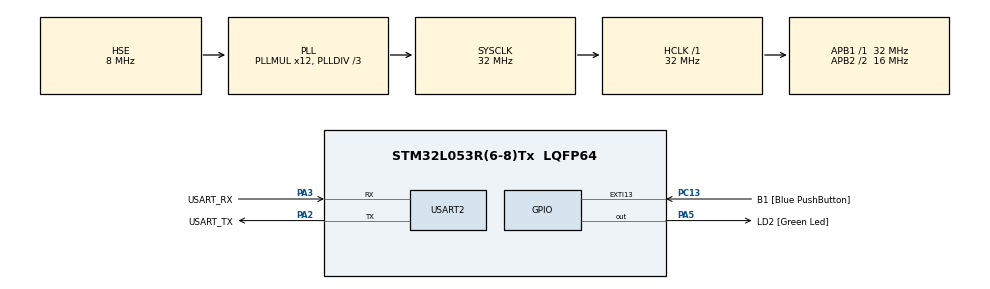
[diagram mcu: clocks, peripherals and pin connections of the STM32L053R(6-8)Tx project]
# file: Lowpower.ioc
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FREERTOS.Tasks01=defaultTask,0,128,StartDefaultTask,Default
Mcu.Family=STM32L0
Mcu.Name=STM32L053R(6-8)Tx
Mcu.Package=LQFP64
NVIC.EXTI4_15_IRQn=true\:3\:0\:false\:false\:true
NVIC.TIM6_DAC_IRQn=true\:0\:0\:false\:false\:true
NVIC.TimeBase=TIM6_DAC_IRQn
NVIC.TimeBaseIP=TIM6
PA13.GPIO_Label=TMS
PA13.Mode=Serial_Wire
PA13.Signal=SYS_SWDIO
PA14.GPIO_Label=TCK
PA14.Mode=Serial_Wire
PA14.Signal=SYS_SWCLK
PA2.GPIO_Label=USART_TX
PA2.Mode=Asynchronous
PA2.Signal=USART2_TX
PA3.GPIO_Label=USART_RX
PA3.Mode=Asynchronous
PA3.Signal=USART2_RX
PA5.GPIO_Label=LD2 [Green Led]
PA5.Signal=GPIO_Output
PC13.GPIO_Label=B1 [Blue PushButton]
PC13.GPIO_ModeDefaultEXTI=GPIO_MODE_IT_RISING
PC13.GPIO_PuPd=GPIO_PULLUP
PC13.Signal=GPXTI13
PC14-OSC32_IN.Mode=LSE-External-Oscillator
PC14-OSC32_IN.Signal=RCC_OSC32_IN
PC15-OSC32_OUT.Mode=LSE-External-Oscillator
PC15-OSC32_OUT.Signal=RCC_OSC32_OUT
PH0-OSC_IN.Signal=RCC_OSC_IN
ProjectManager.HeapSize=0x400
ProjectManager.StackSize=0x800
ProjectManager.TargetToolchain=TrueSTUDIO
RCC.AHBFreq_Value=32000000
RCC.APB1Freq_Value=32000000
RCC.APB1TimFreq_Value=32000000
RCC.APB2CLKDivider=RCC_HCLK_DIV2
RCC.APB2Freq_Value=16000000
RCC.APB2TimFreq_Value=32000000
RCC.HCLKFreq_Value=32000000
RCC.HSE_VALUE=8000000
RCC.HSI16_VALUE=16000000
RCC.HSI48_VALUE=48000000
RCC.HSI_VALUE=16000000
RCC.MSI_VALUE=2097000
RCC.PLLDIV=RCC_PLLDIV_3
RCC.PLLMUL=RCC_PLLMUL_6
RCC.RTCClockSelection=RCC_RTCCLKSOURCE_LSE
RCC.RTCClockSelectionVirtual=RCC_RTCCLKSOURCE_LSE
RCC.SYSCLKFreq_VALUE=32000000
RCC.SYSCLKSource=RCC_SYSCLKSOURCE_PLLCLK
RCC.VCOOutputFreq_Value=96000000
USART2.WordLength=UART_WORDLENGTH_8B
VP_FREERTOS_VS_ENABLE.Mode=Enabled
VP_RTC_VS_RTC_Alarm_A_Intern.Mode=Alarm A
VP_RTC_VS_RTC_WakeUp_intern.Mode=WakeUp
VP_SYS_VS_tim6.Mode=TIM6
board=NUCLEO-L053R8

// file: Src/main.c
/**
  ******************************************************************************
  * File Name          : main.c
  * Description        : Main program body
  ******************************************************************************
  *
  * COPYRIGHT(c) 2016 STMicroelectronics
  *
  * Redistribution and use in source and binary forms, with or without modification,
  * are permitted provided that the following conditions are met:
  *   1. Redistributions of source code must retain the above copyright notice,
  *      this list of conditions and the following disclaimer.
  *   2. Redistributions in binary form must reproduce the above copyright notice,
  *      this list of conditions and the following disclaimer in the documentation
  *      and/or other materials provided with the distribution.
  *   3. Neither the name of STMicroelectronics nor the names of its contributors
  *      may be used to endorse or promote products derived from this software
  *      without specific prior written permission.
  *
  * THIS SOFTWARE IS PROVIDED BY THE COPYRIGHT HOLDERS AND CONTRIBUTORS "AS IS"
  * AND ANY EXPRESS OR IMPLIED WARRANTIES, INCLUDING, BUT NOT LIMITED TO, THE
  * IMPLIED WARRANTIES OF MERCHANTABILITY AND FITNESS FOR A PARTICULAR PURPOSE ARE
  * DISCLAIMED. IN NO EVENT SHALL THE COPYRIGHT HOLDER OR CONTRIBUTORS BE LIABLE
  * FOR ANY DIRECT, INDIRECT, INCIDENTAL, SPECIAL, EXEMPLARY, OR CONSEQUENTIAL
  * DAMAGES (INCLUDING, BUT NOT LIMITED TO, PROCUREMENT OF SUBSTITUTE GOODS OR
  * SERVICES; LOSS OF USE, DATA, OR PROFITS; OR BUSINESS INTERRUPTION) HOWEVER
  * CAUSED AND ON ANY THEORY OF LIABILITY, WHETHER IN CONTRACT, STRICT LIABILITY,
  * OR TORT (INCLUDING NEGLIGENCE OR OTHERWISE) ARISING IN ANY WAY OUT OF THE USE
  * OF THIS SOFTWARE, EVEN IF ADVISED OF THE POSSIBILITY OF SUCH DAMAGE.
  *
  ******************************************************************************
  */
#include "stm32l0xx_hal.h"
#include "cmsis_os.h"

/* USER CODE BEGIN Includes */

#include <stdio.h>

/* USER CODE END Includes */

RTC_HandleTypeDef hrtc;

UART_HandleTypeDef huart2;

osThreadId defaultTaskHandle;

/* USER CODE BEGIN PV */
/* Private variables ---------------------------------------------------------*/

/* USER CODE END PV */

void SystemClock_Config(void);
static void MX_GPIO_Init(void);
static void MX_RTC_Init(void);
static void MX_USART2_UART_Init(void);
void StartDefaultTask(void const * argument);

/* USER CODE BEGIN PFP */
/* Private function prototypes -----------------------------------------------*/

/* USER CODE END PFP */

int main(void)
{

  /* MCU Configuration----------------------------------------------------------*/

  /* Reset of all peripherals, Initializes the Flash interface and the Systick. */
  HAL_Init();

  /* Configure the system clock */
  SystemClock_Config();

  /* Initialize all configured peripherals */
  MX_GPIO_Init();
  MX_RTC_Init();
  MX_USART2_UART_Init();

  /* USER CODE BEGIN 2 */
  HAL_UART_Transmit(&huart2, (uint8_t *)"\n\rDuvitech \302\2512016\n\r", 19, 0x0f);
  /* USER CODE END 2 */

  /* Create the thread(s) */
  /* definition and creation of defaultTask */
  osThreadDef(defaultTask, StartDefaultTask, osPriorityNormal, 0, 128);
  defaultTaskHandle = osThreadCreate(osThread(defaultTask), NULL);

  /* Start scheduler */
  osKernelStart();

  /* We should never get here as control is now taken by the scheduler */

  /* Infinite loop */
  while (1)
  {

  }

}

/** System Clock Configuration
*/
/** System Clock Configuration
*/
void SystemClock_Config(void)
{

  RCC_OscInitTypeDef RCC_OscInitStruct;
  RCC_ClkInitTypeDef RCC_ClkInitStruct;
  RCC_PeriphCLKInitTypeDef PeriphClkInit;

  __HAL_RCC_PWR_CLK_ENABLE();

  __HAL_PWR_VOLTAGESCALING_CONFIG(PWR_REGULATOR_VOLTAGE_SCALE1);

  RCC_OscInitStruct.OscillatorType = RCC_OSCILLATORTYPE_HSE|RCC_OSCILLATORTYPE_LSE;
  RCC_OscInitStruct.HSEState = RCC_HSE_BYPASS;
  RCC_OscInitStruct.LSEState = RCC_LSE_ON;
  RCC_OscInitStruct.PLL.PLLState = RCC_PLL_ON;
  RCC_OscInitStruct.PLL.PLLSource = RCC_PLLSOURCE_HSE;
  RCC_OscInitStruct.PLL.PLLMUL = RCC_PLLMUL_12;
  RCC_OscInitStruct.PLL.PLLDIV = RCC_PLLDIV_3;
  HAL_RCC_OscConfig(&RCC_OscInitStruct);

  RCC_ClkInitStruct.ClockType = RCC_CLOCKTYPE_HCLK|RCC_CLOCKTYPE_SYSCLK
                              |RCC_CLOCKTYPE_PCLK1|RCC_CLOCKTYPE_PCLK2;
  RCC_ClkInitStruct.SYSCLKSource = RCC_SYSCLKSOURCE_PLLCLK;
  RCC_ClkInitStruct.AHBCLKDivider = RCC_SYSCLK_DIV1;
  RCC_ClkInitStruct.APB1CLKDivider = RCC_HCLK_DIV1;
  RCC_ClkInitStruct.APB2CLKDivider = RCC_HCLK_DIV2;
  HAL_RCC_ClockConfig(&RCC_ClkInitStruct, FLASH_LATENCY_1);

  PeriphClkInit.PeriphClockSelection = RCC_PERIPHCLK_USART2|RCC_PERIPHCLK_RTC;
  PeriphClkInit.Usart2ClockSelection = RCC_USART2CLKSOURCE_PCLK1;
  PeriphClkInit.RTCClockSelection = RCC_RTCCLKSOURCE_LSE;
  HAL_RCCEx_PeriphCLKConfig(&PeriphClkInit);

  HAL_SYSTICK_Config(HAL_RCC_GetHCLKFreq()/1000);

  HAL_SYSTICK_CLKSourceConfig(SYSTICK_CLKSOURCE_HCLK);

  /* SysTick_IRQn interrupt configuration */
  HAL_NVIC_SetPriority(SysTick_IRQn, 3, 0);
}

/* RTC init function */
void MX_RTC_Init(void)
{

  RTC_TimeTypeDef sTime;
  RTC_DateTypeDef sDate;
  RTC_AlarmTypeDef sAlarm;

    /**Initialize RTC and set the Time and Date
    */
  hrtc.Instance = RTC;
  hrtc.Init.HourFormat = RTC_HOURFORMAT_24;
  hrtc.Init.AsynchPrediv = 127;
  hrtc.Init.SynchPrediv = 255;
  hrtc.Init.OutPut = RTC_OUTPUT_DISABLE;
  hrtc.Init.OutPutRemap = RTC_OUTPUT_REMAP_NONE;
  hrtc.Init.OutPutPolarity = RTC_OUTPUT_POLARITY_HIGH;
  hrtc.Init.OutPutType = RTC_OUTPUT_TYPE_OPENDRAIN;
  HAL_RTC_Init(&hrtc);

  sTime.Hours = 0x0;
  sTime.Minutes = 0x0;
  sTime.Seconds = 0x0;
  sTime.DayLightSaving = RTC_DAYLIGHTSAVING_NONE;
  sTime.StoreOperation = RTC_STOREOPERATION_RESET;
  HAL_RTC_SetTime(&hrtc, &sTime, RTC_FORMAT_BCD);

  sDate.WeekDay = RTC_WEEKDAY_MONDAY;
  sDate.Month = RTC_MONTH_JANUARY;
  sDate.Date = 0x1;
  sDate.Year = 0x0;

  HAL_RTC_SetDate(&hrtc, &sDate, RTC_FORMAT_BCD);

    /**Enable the Alarm A
    */
  sAlarm.AlarmTime.Hours = 0x0;
  sAlarm.AlarmTime.Minutes = 0x0;
  sAlarm.AlarmTime.Seconds = 0x0;
  sAlarm.AlarmTime.SubSeconds = 0x0;
  sAlarm.AlarmTime.DayLightSaving = RTC_DAYLIGHTSAVING_NONE;
  sAlarm.AlarmTime.StoreOperation = RTC_STOREOPERATION_RESET;
  sAlarm.AlarmMask = RTC_ALARMMASK_NONE;
  sAlarm.AlarmSubSecondMask = RTC_ALARMSUBSECONDMASK_ALL;
  sAlarm.AlarmDateWeekDaySel = RTC_ALARMDATEWEEKDAYSEL_DATE;
  sAlarm.AlarmDateWeekDay = 0x1;
  sAlarm.Alarm = RTC_ALARM_A;
  HAL_RTC_SetAlarm(&hrtc, &sAlarm, RTC_FORMAT_BCD);

    /**Enable the WakeUp
    */
  HAL_RTCEx_SetWakeUpTimer(&hrtc, 0, RTC_WAKEUPCLOCK_RTCCLK_DIV16);

}

/* USART2 init function */
void MX_USART2_UART_Init(void)
{

  huart2.Instance = USART2;
  huart2.Init.BaudRate = 115200;
  huart2.Init.WordLength = UART_WORDLENGTH_8B;
  huart2.Init.StopBits = UART_STOPBITS_1;
  huart2.Init.Parity = UART_PARITY_NONE;
  huart2.Init.Mode = UART_MODE_TX_RX;
  huart2.Init.HwFlowCtl = UART_HWCONTROL_NONE;
  huart2.Init.OverSampling = UART_OVERSAMPLING_16;
  huart2.Init.OneBitSampling = UART_ONE_BIT_SAMPLE_DISABLE;
  huart2.AdvancedInit.AdvFeatureInit = UART_ADVFEATURE_NO_INIT;
  HAL_UART_Init(&huart2);

}

/** Configure pins as
        * Analog
        * Input
        * Output
        * EVENT_OUT
        * EXTI
        * Free pins are configured automatically as Analog (this feature is enabled through
        * the Code Generation settings)
*/
void MX_GPIO_Init(void)
{

  GPIO_InitTypeDef GPIO_InitStruct;

  /* GPIO Ports Clock Enable */
  __HAL_RCC_GPIOC_CLK_ENABLE();
  __HAL_RCC_GPIOH_CLK_ENABLE();
  __HAL_RCC_GPIOA_CLK_ENABLE();
  __HAL_RCC_GPIOB_CLK_ENABLE();
  __HAL_RCC_GPIOD_CLK_ENABLE();

  /*Configure GPIO pin : B1_Pin */
  GPIO_InitStruct.Pin = B1_Pin;
  GPIO_InitStruct.Mode = GPIO_MODE_IT_RISING;
  GPIO_InitStruct.Pull = GPIO_PULLUP;
  HAL_GPIO_Init(B1_GPIO_Port, &GPIO_InitStruct);

  /*Configure GPIO pin : PH1 */
  GPIO_InitStruct.Pin = GPIO_PIN_1;
  GPIO_InitStruct.Mode = GPIO_MODE_ANALOG;
  GPIO_InitStruct.Pull = GPIO_NOPULL;
  HAL_GPIO_Init(GPIOH, &GPIO_InitStruct);

  /*Configure GPIO pins : PC0 PC1 PC2 PC3
                           PC4 PC5 PC6 PC7
                           PC8 PC9 PC10 PC11
                           PC12 */
  GPIO_InitStruct.Pin = GPIO_PIN_0|GPIO_PIN_1|GPIO_PIN_2|GPIO_PIN_3
                          |GPIO_PIN_4|GPIO_PIN_5|GPIO_PIN_6|GPIO_PIN_7
                          |GPIO_PIN_8|GPIO_PIN_9|GPIO_PIN_10|GPIO_PIN_11
                          |GPIO_PIN_12;
  GPIO_InitStruct.Mode = GPIO_MODE_ANALOG;
  GPIO_InitStruct.Pull = GPIO_NOPULL;
  HAL_GPIO_Init(GPIOC, &GPIO_InitStruct);

  /*Configure GPIO pins : PA0 PA1 PA4 PA6
                           PA7 PA8 PA9 PA10
                           PA11 PA12 PA15 */
  GPIO_InitStruct.Pin = GPIO_PIN_0|GPIO_PIN_1|GPIO_PIN_4|GPIO_PIN_6
                          |GPIO_PIN_7|GPIO_PIN_8|GPIO_PIN_9|GPIO_PIN_10
                          |GPIO_PIN_11|GPIO_PIN_12|GPIO_PIN_15;
  GPIO_InitStruct.Mode = GPIO_MODE_ANALOG;
  GPIO_InitStruct.Pull = GPIO_NOPULL;
  HAL_GPIO_Init(GPIOA, &GPIO_InitStruct);

  /*Configure GPIO pin : LD2_Pin */
  GPIO_InitStruct.Pin = LD2_Pin;
  GPIO_InitStruct.Mode = GPIO_MODE_OUTPUT_PP;
  GPIO_InitStruct.Pull = GPIO_NOPULL;
  GPIO_InitStruct.Speed = GPIO_SPEED_FREQ_LOW;
  HAL_GPIO_Init(LD2_GPIO_Port, &GPIO_InitStruct);

  /*Configure GPIO pins : PB0 PB1 PB2 PB10
                           PB11 PB12 PB13 PB14
                           PB15 PB3 PB4 PB5
                           PB6 PB7 PB8 PB9 */
  GPIO_InitStruct.Pin = GPIO_PIN_0|GPIO_PIN_1|GPIO_PIN_2|GPIO_PIN_10
                          |GPIO_PIN_11|GPIO_PIN_12|GPIO_PIN_13|GPIO_PIN_14
                          |GPIO_PIN_15|GPIO_PIN_3|GPIO_PIN_4|GPIO_PIN_5
                          |GPIO_PIN_6|GPIO_PIN_7|GPIO_PIN_8|GPIO_PIN_9;
  GPIO_InitStruct.Mode = GPIO_MODE_ANALOG;
  GPIO_InitStruct.Pull = GPIO_NOPULL;
  HAL_GPIO_Init(GPIOB, &GPIO_InitStruct);

  /*Configure GPIO pin : PD2 */
  GPIO_InitStruct.Pin = GPIO_PIN_2;
  GPIO_InitStruct.Mode = GPIO_MODE_ANALOG;
  GPIO_InitStruct.Pull = GPIO_NOPULL;
  HAL_GPIO_Init(GPIOD, &GPIO_InitStruct);

  /*Configure GPIO pin Output Level */
  HAL_GPIO_WritePin(LD2_GPIO_Port, LD2_Pin, GPIO_PIN_RESET);

  /* EXTI interrupt init*/
  HAL_NVIC_SetPriority(EXTI4_15_IRQn, 3, 0);
  HAL_NVIC_EnableIRQ(EXTI4_15_IRQn);

}

/* StartDefaultTask function */
void StartDefaultTask(void const * argument)
{

  /* USER CODE BEGIN 5 */
  printf("Low Power Demo\n\r\n\r");
  /* Infinite loop */
  for(;;)
  {
	HAL_GPIO_TogglePin(LD2_GPIO_Port, LD2_Pin);
    osDelay(500);
  }
  /* USER CODE END 5 */
}

/************************ (C) COPYRIGHT STMicroelectronics *****END OF FILE****/
